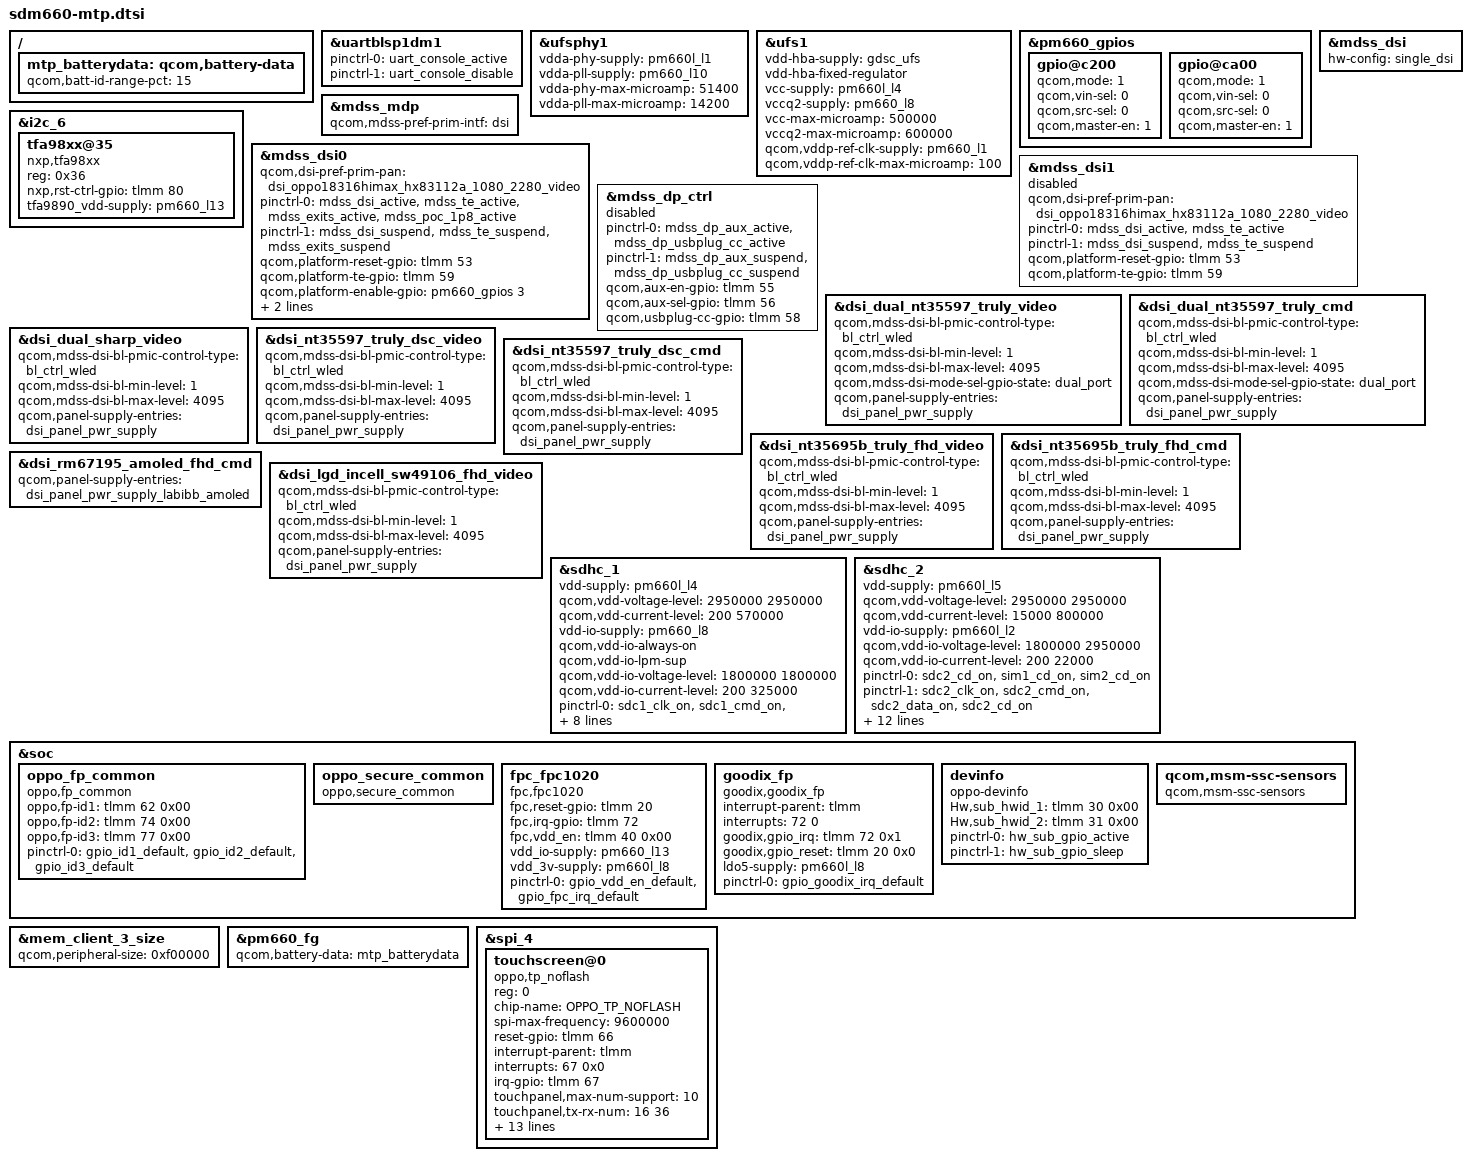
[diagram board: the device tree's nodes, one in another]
/* Copyright (c) 2016-2018, The Linux Foundation. All rights reserved.
 *
 * This program is free software; you can redistribute it and/or modify
 * it under the terms of the GNU General Public License version 2 and
 * only version 2 as published by the Free Software Foundation.
 *
 * This program is distributed in the hope that it will be useful,
 * but WITHOUT ANY WARRANTY; without even the implied warranty of
 * MERCHANTABILITY or FITNESS FOR A PARTICULAR PURPOSE.  See the
 * GNU General Public License for more details.
 */

#include "sdm660-pinctrl.dtsi"
#include "sdm660-camera-sensor-mtp.dtsi"
/ {
	mtp_batterydata: qcom,battery-data {
		qcom,batt-id-range-pct = <15>;
		#include "fg-gen3-batterydata-atl-3000mah.dtsi"
		#include "fg-gen3-batterydata-itech-3000mah.dtsi"
		#include "fg-gen3-batterydata-ascent-3450mah.dtsi"
	};
};

&uartblsp1dm1 {
	status = "ok";
//#ifdef CONFIG_PRODUCT_REALME_RMX1801 /* Jianchao.Shi@BSP.CHG.Basic, 2017/04/10, sjc Modify for console */
	//pinctrl-names = "default";
	//pinctrl-0 = <&uart_console_active>;
//#else
	pinctrl-names = "default", "disable";
	pinctrl-0 = <&uart_console_active>;
	pinctrl-1 = <&uart_console_disable>;
//#endif /* CONFIG_PRODUCT_REALME_RMX1801 */
};

&ufsphy1 {
	vdda-phy-supply = <&pm660l_l1>;
	vdda-pll-supply = <&pm660_l10>;
	vdda-phy-max-microamp = <51400>;
	vdda-pll-max-microamp = <14200>;
	status = "ok";
};

&ufs1 {
	vdd-hba-supply = <&gdsc_ufs>;
	vdd-hba-fixed-regulator;
	vcc-supply = <&pm660l_l4>;
	vccq2-supply = <&pm660_l8>;
	vcc-max-microamp = <500000>;
	vccq2-max-microamp = <600000>;
	qcom,vddp-ref-clk-supply = <&pm660_l1>;
	qcom,vddp-ref-clk-max-microamp = <100>;

	status = "ok";
};

&pm660_gpios {
//#ifdef CONFIG_PRODUCT_REALME_RMX1801
//Gou shegnjun@PSW.MM.Display.LCD.Stability, 2018/05/21,
//add for lcd gpio
	/* GPIO 4 (NFC_CLK_REQ) */
    /*gpio@c300 {
		qcom,mode = <0>;
		qcom,vin-sel = <1>;
		qcom,src-sel = <0>;
		qcom,master-en = <1>;
		status = "okay";
	};*/

	/* GPIO 11 for Home Key */
	/*gpio@ca00 {
		status = "okay";
		qcom,mode = <0>;
		qcom,pull = <0>;
		qcom,vin-sel = <0>;
		qcom,src-sel = <0>;
		qcom,out-strength = <1>;
	};*/
//#else /* CONFIG_PRODUCT_REALME_RMX1801 */
	/* GPIO 3 for : +5v */
	gpio@c200 {
		qcom,mode = <1>;
		qcom,vin-sel = <0>;
		qcom,src-sel = <0>;
		qcom,master-en = <1>;
		status = "okay";
	};

	/* GPIO 11 for: -5v */
	gpio@ca00 {
		qcom,mode = <1>;
		qcom,vin-sel = <0>;
		qcom,src-sel = <0>;
		qcom,master-en = <1>;
		status = "okay";
	};
//#endif /* CONFIG_PRODUCT_REALME_RMX1801 */
};

&i2c_6 { /* BLSP1 QUP6 (NFC) */
	status = "okay";
//#ifdef CONFIG_PRODUCT_REALME_RMX1801
//wenjie.Liu@CN.NFC.Basic.Hardware.1164987, 2018/06/10,
// Remove for:NXP NQ330-NFC(driver_config)
/*
	nq@28 {
		compatible = "qcom,nq-nci";
		reg = <0x28>;
		qcom,nq-irq = <&tlmm 28 0x00>;
		qcom,nq-ven = <&tlmm 29 0x00>;
		qcom,nq-firm = <&tlmm 30 0x00>;
		qcom,nq-clkreq = <&pm660_gpios 4 0x00>;
		qcom,nq-esepwr = <&tlmm 31 0x00>;
		interrupt-parent = <&tlmm>;
		qcom,clk-src = "BBCLK3";
		interrupts = <28 0>;
		interrupt-names = "nfc_irq";
		pinctrl-names = "nfc_active", "nfc_suspend";
		pinctrl-0 = <&nfc_int_active &nfc_enable_active>;
		pinctrl-1 = <&nfc_int_suspend &nfc_enable_suspend>;
		clocks = <&clock_rpmcc RPM_LN_BB_CLK3_PIN>;
		clock-names = "ref_clk";
	};
*/
//#endif /* CONFIG_PRODUCT_REALME_RMX1801 */
};

&mdss_mdp {
	qcom,mdss-pref-prim-intf = "dsi";
};

//#ifdef CONFIG_PRODUCT_REALME_RMX1801
//Gou shengjun@PSW.MM.Display.LCD.Stability, 2017/11/30,
//add for panel config
/*
&mdss_dsi {
	hw-config = "split_dsi";
};

&mdss_dsi0 {
	qcom,dsi-pref-prim-pan = <&dsi_dual_nt35597_truly_video>;
	pinctrl-names = "mdss_default", "mdss_sleep";
	pinctrl-0 = <&mdss_dsi_active &mdss_te_active>;
	pinctrl-1 = <&mdss_dsi_suspend &mdss_te_suspend>;
	qcom,platform-reset-gpio = <&tlmm 53 0>;
	qcom,platform-te-gpio = <&tlmm 59 0>;
};

&mdss_dsi1 {
	qcom,dsi-pref-prim-pan = <&dsi_dual_nt35597_truly_video>;
	pinctrl-names = "mdss_default", "mdss_sleep";
	pinctrl-0 = <&mdss_dsi_active &mdss_te_active>;
	pinctrl-1 = <&mdss_dsi_suspend &mdss_te_suspend>;
	qcom,platform-reset-gpio = <&tlmm 53 0>;
	qcom,platform-te-gpio = <&tlmm 59 0>;
};
*/

&mdss_dsi {
	hw-config = "single_dsi";
};

//Gou shegnjun@PSW.MM.Display.LCD.Stability, 2017/11/30,
//add for lcd gpio config
&mdss_dsi0 {
	qcom,dsi-pref-prim-pan = <&dsi_oppo18316himax_hx83112a_1080_2280_video>;
	pinctrl-names = "mdss_default", "mdss_sleep";
	pinctrl-0 = <&mdss_dsi_active &mdss_te_active &mdss_exits_active &mdss_poc_1p8_active>;
	pinctrl-1 = <&mdss_dsi_suspend &mdss_te_suspend &mdss_exits_suspend>;
	qcom,platform-reset-gpio = <&tlmm 53 0>;
	qcom,platform-te-gpio = <&tlmm 59 0>;
	qcom,platform-enable-gpio = <&pm660_gpios 3 0>;              /* GPIO_01 LCD_5V_ENP */
	qcom,platform-enable-negative-gpio = <&pm660_gpios 11 0>;    /* GPIO_11 LCD_5V_ENN */
};

&mdss_dsi1 {
	status = "disabled";
	qcom,dsi-pref-prim-pan = <&dsi_oppo18316himax_hx83112a_1080_2280_video>;
	pinctrl-names = "mdss_default", "mdss_sleep";
	pinctrl-0 = <&mdss_dsi_active &mdss_te_active>;
	pinctrl-1 = <&mdss_dsi_suspend &mdss_te_suspend>;
	qcom,platform-reset-gpio = <&tlmm 53 0>;
	qcom,platform-te-gpio = <&tlmm 59 0>;
};
//#endif /*CONFIG_PRODUCT_REALME_RMX1801*/

&mdss_dp_ctrl {
//#ifdef CONFIG_PRODUCT_REALME_RMX1801
//Gou shegnjun@PSW.MM.Display.LCD.Stability, 2018/05/24,
//add for disable display port
	status = "disabled";
//#endif
	pinctrl-names = "mdss_dp_active", "mdss_dp_sleep";
	pinctrl-0 = <&mdss_dp_aux_active &mdss_dp_usbplug_cc_active>;
	pinctrl-1 = <&mdss_dp_aux_suspend &mdss_dp_usbplug_cc_suspend>;
	qcom,aux-en-gpio = <&tlmm 55 0>;
	qcom,aux-sel-gpio = <&tlmm 56 0>;
	qcom,usbplug-cc-gpio = <&tlmm 58 0>;
};

//#ifndef CONFIG_PRODUCT_REALME_RMX1801
/* Gou shegnjun@PSW.MM.Display.LCD.Stability, 2017/07/10, delete */
//&pm660l_wled {
//	qcom,led-strings-list = [01 02];
//};
//#endif

&dsi_dual_nt35597_truly_video {
	qcom,mdss-dsi-bl-pmic-control-type = "bl_ctrl_wled";
	qcom,mdss-dsi-bl-min-level = <1>;
	qcom,mdss-dsi-bl-max-level = <4095>;
	qcom,mdss-dsi-mode-sel-gpio-state = "dual_port";
	qcom,panel-supply-entries = <&dsi_panel_pwr_supply>;
};

&dsi_dual_nt35597_truly_cmd {
	qcom,mdss-dsi-bl-pmic-control-type = "bl_ctrl_wled";
	qcom,mdss-dsi-bl-min-level = <1>;
	qcom,mdss-dsi-bl-max-level = <4095>;
	qcom,mdss-dsi-mode-sel-gpio-state = "dual_port";
	qcom,panel-supply-entries = <&dsi_panel_pwr_supply>;
};

&dsi_dual_sharp_video {
	qcom,mdss-dsi-bl-pmic-control-type = "bl_ctrl_wled";
	qcom,mdss-dsi-bl-min-level = <1>;
	qcom,mdss-dsi-bl-max-level = <4095>;
	qcom,panel-supply-entries = <&dsi_panel_pwr_supply>;
};

&dsi_nt35597_truly_dsc_video {
	qcom,mdss-dsi-bl-pmic-control-type = "bl_ctrl_wled";
	qcom,mdss-dsi-bl-min-level = <1>;
	qcom,mdss-dsi-bl-max-level = <4095>;
	qcom,panel-supply-entries = <&dsi_panel_pwr_supply>;
};

&dsi_nt35597_truly_dsc_cmd {
	qcom,mdss-dsi-bl-pmic-control-type = "bl_ctrl_wled";
	qcom,mdss-dsi-bl-min-level = <1>;
	qcom,mdss-dsi-bl-max-level = <4095>;
	qcom,panel-supply-entries = <&dsi_panel_pwr_supply>;
};

&dsi_nt35695b_truly_fhd_video {
	qcom,mdss-dsi-bl-pmic-control-type = "bl_ctrl_wled";
	qcom,mdss-dsi-bl-min-level = <1>;
	qcom,mdss-dsi-bl-max-level = <4095>;
	qcom,panel-supply-entries = <&dsi_panel_pwr_supply>;
};

&dsi_nt35695b_truly_fhd_cmd {
	qcom,mdss-dsi-bl-pmic-control-type = "bl_ctrl_wled";
	qcom,mdss-dsi-bl-min-level = <1>;
	qcom,mdss-dsi-bl-max-level = <4095>;
	qcom,panel-supply-entries = <&dsi_panel_pwr_supply>;
};

&dsi_rm67195_amoled_fhd_cmd {
	qcom,panel-supply-entries = <&dsi_panel_pwr_supply_labibb_amoled>;
};

//#endif /*CONFIG_PRODUCT_REALME_RMX1801*/

&dsi_lgd_incell_sw49106_fhd_video {
	qcom,mdss-dsi-bl-pmic-control-type = "bl_ctrl_wled";
	qcom,mdss-dsi-bl-min-level = <1>;
	qcom,mdss-dsi-bl-max-level = <4095>;
	qcom,panel-supply-entries = <&dsi_panel_pwr_supply>;
};

&sdhc_1 {
	/* device core power supply */
	vdd-supply = <&pm660l_l4>;
	qcom,vdd-voltage-level = <2950000 2950000>;
	qcom,vdd-current-level = <200 570000>;

	/* device communication power supply */
	vdd-io-supply = <&pm660_l8>;
	qcom,vdd-io-always-on;
	qcom,vdd-io-lpm-sup;
	qcom,vdd-io-voltage-level = <1800000 1800000>;
	qcom,vdd-io-current-level = <200 325000>;

	pinctrl-names = "active", "sleep";
	pinctrl-0 = <&sdc1_clk_on &sdc1_cmd_on &sdc1_data_on &sdc1_rclk_on>;
	pinctrl-1 = <&sdc1_clk_off &sdc1_cmd_off &sdc1_data_off &sdc1_rclk_off>;

	qcom,clk-rates = <400000 20000000 25000000 50000000 100000000 192000000
								384000000>;

	qcom,nonremovable;
	qcom,bus-speed-mode = "HS400_1p8v", "HS200_1p8v", "DDR_1p8v";

	status = "ok";
};

&sdhc_2 {
	/* device core power supply */
	//#ifndef CONFIG_PRODUCT_REALME_RMX1801
//Fanhong.Kong@PSW.BSP.CHG,,2018/05/25,Added for PM660L L5
	vdd-supply = <&pm660l_l5>;
//#else
//	vdd-supply = <&sdhc2_vdd_vreg>;
//#endif
	
	qcom,vdd-voltage-level = <2950000 2950000>;
	qcom,vdd-current-level = <15000 800000>;

	/* device communication power supply */
	vdd-io-supply = <&pm660l_l2>;
	qcom,vdd-io-voltage-level = <1800000 2950000>;
	qcom,vdd-io-current-level = <200 22000>;
	
//#ifndef CONFIG_PRODUCT_REALME_RMX1801
//rendong.shi@Bsp.Storage.card,2016/12/21,Added for vdd_en using gpio supply 3V
	pinctrl-names = "default", "active", "sleep";
	pinctrl-0 = <&sdc2_cd_on &sim1_cd_on &sim2_cd_on>;
	pinctrl-1 = <&sdc2_clk_on  &sdc2_cmd_on &sdc2_data_on &sdc2_cd_on>;
	pinctrl-2 = <&sdc2_clk_off &sdc2_cmd_off &sdc2_data_off &sdc2_cd_off>;
//#endif
	

	#address-cells = <0>;
	interrupt-parent = <&sdhc_2>;
	interrupts = <0 1 2>;
	#interrupt-cells = <1>;
	interrupt-map-mask = <0xffffffff>;
	interrupt-map = <0 &intc 0 0 125 0
			1 &intc 0 0 221 0
			2 &tlmm 54 0>;
	interrupt-names = "hc_irq", "pwr_irq", "status_irq";
	//#ifndef CONFIG_PRODUCT_REALME_RMX1801
//rendong.shi@Bsp.Storage.card,2016/12/21,Added for vdd_en using gpio supply 3V
	cd-gpios = <&tlmm 54 0x0>;
//#endif
	qcom,clk-rates = <400000 20000000 25000000 50000000 100000000
								200000000>;
	qcom,bus-speed-mode = "SDR12", "SDR25", "SDR50", "DDR50", "SDR104";

	status = "ok";
};

&soc {

/*#ifdef CONFIG_PRODUCT_REALME_RMX1801 ziqing.guo@phone.bsp 2016-07-23 add for fingerprint compatibility */
    oppo_fp_common { //Slave driver and CS ID
        compatible = "oppo,fp_common"; //Manufacture, and Model
        oppo,fp-id1 = <&tlmm 62 0x00>;
        oppo,fp-id2 = <&tlmm 74 0x00>;
        oppo,fp-id3 = <&tlmm 77 0x00>;
        pinctrl-names = "default";
        pinctrl-0 = <&gpio_id1_default &gpio_id2_default &gpio_id3_default>;
    };
    oppo_secure_common { //Slave driver and CS ID
        compatible = "oppo,secure_common"; //Manufacture, and Model
    };
/*#endif CONFIG_PRODUCT_REALME_RMX1801 */

/*#ifdef CONFIG_PRODUCT_REALME_RMX1801 ziqing.guo@phone.bsp 2015-12-20 add for fpc TEE */
    fpc_fpc1020 { //Slave driver and CS ID
        compatible = "fpc,fpc1020"; //Manufacture, and Model
        fpc,reset-gpio = <&tlmm 20 0x00>;
        fpc,irq-gpio = <&tlmm 72 0x00>;
        fpc,vdd_en = <&tlmm 40 0x00>;
        vdd_io-supply = <&pm660_l13>;   // 1.8V
        vdd_3v-supply = <&pm660l_l8>;  // 3V
        pinctrl-names = "default";
        pinctrl-0 = <&gpio_vdd_en_default &gpio_fpc_irq_default>;
    };
/*#endif CONFIG_PRODUCT_REALME_RMX1801 */

/*#ifdef CONFIG_PRODUCT_REALME_RMX1801 */
/* ziqing.guo@BSP.Fingerprint.Basic, 2017/04/19, add for goodix fingerprint 5288 */
    goodix_fp {
        compatible = "goodix,goodix_fp";
        interrupt-parent = <&tlmm>;
        interrupts = <72 0>;
        goodix,gpio_irq = <&tlmm 72 0x1>;
        goodix,gpio_reset = <&tlmm 20 0x0>;
        ldo5-supply = <&pm660l_l8>;  // pm660l_l8 for goodix_fp
        pinctrl-names = "default";
        pinctrl-0 = <&gpio_goodix_irq_default>;
    };
//#endif /*CONFIG_PRODUCT_REALME_RMX1801*/

/*ifdef CONFIG_PRODUCT_REALME_RMX1801*/
//Added by Tong.han@Bsp.Group.Tp for device-info,2015-4-13
	devinfo {
		compatible = "oppo-devinfo";

		Hw,sub_hwid_1 = <&tlmm 30 0x00>;
		Hw,sub_hwid_2 = <&tlmm 31 0x00>;
		pinctrl-names = "default","hw_sub_gpio_sleep";
		pinctrl-0 = <&hw_sub_gpio_active>;
		pinctrl-1 = <&hw_sub_gpio_sleep>;

	};
/*endif*/

	qcom,msm-ssc-sensors {
		compatible = "qcom,msm-ssc-sensors";
	};
};

&mem_client_3_size {
	qcom,peripheral-size = <0xf00000>;
};

&pm660_fg {
	qcom,battery-data = <&mtp_batterydata>;
};

//#ifdef CONFIG_PRODUCT_REALME_RMX1801
/* ZhongWenjie@BSP.TP.Basic, 2018/05/22, add for nt36672 noflash */
&spi_4 {
	/* Novatek device tree node */
	status = "ok";
	touchscreen@0 {
		compatible = "oppo,tp_noflash";
		reg = <0>;
		chip-name = "OPPO_TP_NOFLASH";
		status = "ok";

		spi-max-frequency = <9600000>;	//4800000,9600000,15000000,19200000
		reset-gpio = <&tlmm 66 0x00>;
		interrupt-parent = <&tlmm>;
		interrupts = <67 0x0>;
		irq-gpio = <&tlmm 67 0x2002>;

		touchpanel,max-num-support = <10>;
		touchpanel,tx-rx-num = <16 36>;
		touchpanel,panel-coords = <1080 2340>;
		touchpanel,display-coords = <1080 2340>;

		incell_screen;
		fw_edge_limit_support;
		black_gesture_support;
		charger_pump_support;
		esd_handle_support;
		game_switch_support;
		//spurious_fingerprint_support;
		//lcd_trigger_fp_check;
		black_gesture_test_support;
		noflash_support;
		smart_gesture_support;
		lcd_trigger_load_tp_fw_support;

		/*
		*Virtual Key Config:
		*1:touchpanel,button-type: <virtualkey_type  supportted_button-map>
		*virtualkey_type:
		*Type 1: using board_properties
		*Type 2: using same IC (button zone&& touch zone are seprate)
		*Type 3: using diffrent IC (button zone&& touch zone are seprate)
		*Type 4: No need of virtual key process
		*supportted_button-map:select|menu|home|back
		*
		*2:touchpanel,button-map
		*type (X1,Y1)(X2,Y2)(X3,Y3)(Width_X,Hight_Y)--Only when button-type is 0
		*/

		touchpanel,button-type = <4>;
	};

};
//#endif
//#ifdef CONFIG_PRODUCT_REALME_RMX1801 /* Jianchao.Shi@BSP.CHG.Basic, 2016/12/20, sjc Add for charging */
/*&i2c_2 {
	status = "ok";
	smb1351-charger@1d {
		compatible = "qcom,smb1351-charger";
		reg = <0x1d>;
		qcom,parallel-charger;
		qcom,float-voltage-mv = <4400>;
		qcom,recharge-mv = <100>;
		qcom,parallel-en-pin-polarity = <1>;
	};

	bq27541-battery@55 {
		status = "okay";
		compatible = "oppo,bq27541-battery";
		reg = <0x55>;
		qcom,modify-soc-smooth;
	};

	stm8s_fastcg@26{
		status = "okay";
		compatible = "oppo,stm8s-fastcg";
		reg = <0x26>;
		qcom,oppo_batt_4400mv;
		qcom,vooc-fw-type = <5>;

		pinctrl-names = "switch1_act_switch2_act", "switch1_sleep_switch2_sleep",
						"switch1_act_switch3_act", "switch1_sleep_switch3_sleep",
						"switch1_act_switch2_sleep", "switch1_sleep_switch2_act",
						"clock_active","clock_sleep",
						"data_active","data_sleep",
						"reset_active","reset_sleep";
		pinctrl-0 = <&charging_switch1_active>;
		pinctrl-1 = <&charging_switch1_sleep >;
		pinctrl-2 = <&charging_switch1_active>;
		pinctrl-3 = <&charging_switch1_sleep >;
		pinctrl-4 = <&charging_switch1_active>;
		pinctrl-5 = <&charging_switch1_sleep>;
		pinctrl-6 = <&charging_clock_active >;
		pinctrl-7 = <&charging_clock_sleep >;
		pinctrl-8 = <&charging_data_active >;
		pinctrl-9 = <&charging_data_sleep >;
		pinctrl-10 = <&charging_reset_active >;
		pinctrl-11 = <&charging_reset_sleep >;

		qcom,charging_switch1-gpio = <&tlmm 75 0x00>;
		//qcom,charging_switch2-gpio = <&tlmm 113 0x00>;
		//qcom,charging_switch3-gpio = <&tlmm 38 0x00>;

		qcom,charging_reset-gpio = <&tlmm 55 0x00>;
		qcom,charging_clock-gpio = <&tlmm 51 0x00>;
		qcom,charging_data-gpio = <&tlmm 44 0x00>;
	};

	pic16f_fastcg@25{
		status = "okay";
		compatible = "oppo,pic16f-fastcg";
		reg = <0x25>;

		pinctrl-names = "switch1_act_switch2_act", "switch1_sleep_switch2_sleep",
						"switch1_act_switch3_act", "switch1_sleep_switch3_sleep",
						"switch1_act_switch2_sleep", "switch1_sleep_switch2_act",
						"clock_active","clock_sleep",
						"data_active","data_sleep",
						"reset_active","reset_sleep";
		pinctrl-0 = <&charging_switch1_active>;
		pinctrl-1 = <&charging_switch1_sleep >;
		pinctrl-2 = <&charging_switch1_active>;
		pinctrl-3 = <&charging_switch1_sleep >;
		pinctrl-4 = <&charging_switch1_active>;
		pinctrl-5 = <&charging_switch1_sleep>;
		pinctrl-6 = <&charging_clock_active >;
		pinctrl-7 = <&charging_clock_sleep >;
		pinctrl-8 = <&charging_data_active >;
		pinctrl-9 = <&charging_data_sleep >;
		pinctrl-10 = <&charging_reset_active >;
		pinctrl-11 = <&charging_reset_sleep >;

		qcom,charging_switch1-gpio = <&tlmm 75 0x00>;
		//qcom,charging_switch2-gpio = <&tlmm 113 0x00>;
		//qcom,charging_switch3-gpio = <&tlmm 38 0x00>;

		qcom,charging_reset-gpio = <&tlmm 55 0x00>;
		qcom,charging_clock-gpio = <&tlmm 51 0x00>;
		qcom,charging_data-gpio = <&tlmm 44 0x00>;
	};
};*/
//#endif

//#ifdef CONFIG_PRODUCT_REALME_RMX1801
/* Yongzhi.Zhang@PSW.MM.AudioDriver.Machine, 2018/06/27, Add for tfa9890 config */
&i2c_6 { /*  BLSP2 QUP2 */
	status = "okay";
	tfa98xx@35 {
		compatible = "nxp,tfa98xx";
		reg = <0x36>;
		nxp,rst-ctrl-gpio = <&tlmm 80 0x00>;
		tfa9890_vdd-supply = <&pm660_l13>;
		status = "okay";
	};
};
//#endif /* CONFIG_PRODUCT_REALME_RMX1801 */
